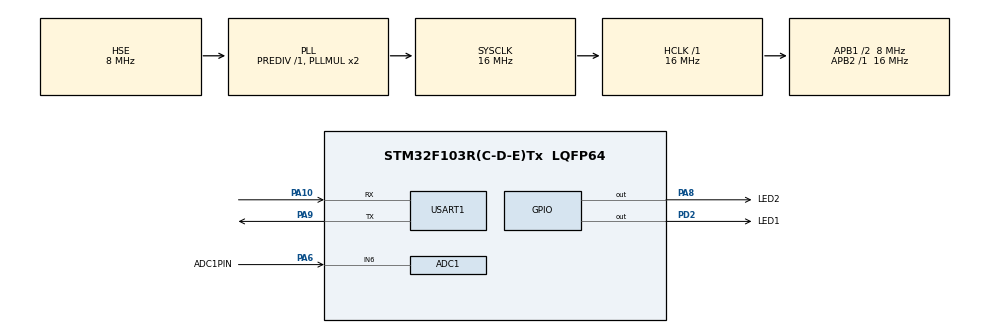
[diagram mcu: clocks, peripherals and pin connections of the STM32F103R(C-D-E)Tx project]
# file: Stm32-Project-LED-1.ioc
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ADC1.Channel-0\#ChannelRegularConversion=ADC_CHANNEL_6
ADC1.NbrOfConversionFlag=1
ADC1.Rank-0\#ChannelRegularConversion=1
ADC1.SamplingTime-0\#ChannelRegularConversion=ADC_SAMPLETIME_1CYCLE_5
ADC1.master=1
Mcu.Family=STM32F1
Mcu.Name=STM32F103R(C-D-E)Tx
Mcu.Package=LQFP64
NVIC.PriorityGroup=NVIC_PRIORITYGROUP_4
PA10.Mode=Asynchronous
PA10.Signal=USART1_RX
PA13.Mode=Serial_Wire
PA13.Signal=SYS_JTMS-SWDIO
PA14.Mode=Serial_Wire
PA14.Signal=SYS_JTCK-SWCLK
PA6.GPIO_Label=ADC1PIN
PA6.Signal=ADCx_IN6
PA8.GPIO_Label=LED2
PA8.GPIO_PuPd=GPIO_PULLUP
PA8.GPIO_Speed=GPIO_SPEED_FREQ_HIGH
PA8.PinState=GPIO_PIN_SET
PA8.Signal=GPIO_Output
PA9.Mode=Asynchronous
PA9.Signal=USART1_TX
PD0-OSC_IN.Mode=HSE-External-Oscillator
PD0-OSC_IN.Signal=RCC_OSC_IN
PD1-OSC_OUT.Mode=HSE-External-Oscillator
PD1-OSC_OUT.Signal=RCC_OSC_OUT
PD2.GPIO_Label=LED1
PD2.GPIO_PuPd=GPIO_PULLUP
PD2.GPIO_Speed=GPIO_SPEED_FREQ_HIGH
PD2.PinState=GPIO_PIN_SET
PD2.Signal=GPIO_Output
ProjectManager.HeapSize=0x200
ProjectManager.StackSize=0x400
ProjectManager.TargetToolchain=MDK-ARM V5.32
RCC.ADCPresc=RCC_ADCPCLK2_DIV8
RCC.AHBFreq_Value=16000000
RCC.APB1CLKDivider=RCC_HCLK_DIV2
RCC.APB1Freq_Value=8000000
RCC.APB1TimFreq_Value=16000000
RCC.APB2Freq_Value=16000000
RCC.APB2TimFreq_Value=16000000
RCC.HCLKFreq_Value=16000000
RCC.PLLSourceVirtual=RCC_PLLSOURCE_HSE
RCC.SYSCLKFreq_VALUE=16000000
RCC.SYSCLKSource=RCC_SYSCLKSOURCE_PLLCLK
RCC.USBFreq_Value=16000000
SH.ADCx_IN6.0=ADC1_IN6,IN6
USART1.VirtualMode=VM_ASYNC
board=custom

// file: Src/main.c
/* USER CODE BEGIN Header */
/**
  ******************************************************************************
  * @file           : main.c
  * @brief          : Main program body
  ******************************************************************************
  * @attention
  *
  * Copyright (c) 2023 STMicroelectronics.
  * All rights reserved.
  *
  * This software is licensed under terms that can be found in the LICENSE file
  * in the root directory of this software component.
  * If no LICENSE file comes with this software, it is provided AS-IS.
  *
  ******************************************************************************
  */
/* USER CODE END Header */
#include "main.h"
#include "adc.h"
#include "usart.h"
#include "gpio.h"

/* USER CODE BEGIN Includes */
#include "stdio.h"
/* USER CODE END Includes */

/* USER CODE BEGIN PV */
uint16_t ADC1Val=0;
//char ss[]="";
/* USER CODE END PV */

void SystemClock_Config(void);

/* USER CODE BEGIN 0 */
int fputc(int ch,FILE *f)
{
	HAL_UART_Transmit(&huart1,(uint8_t *) &ch,1,0xfff);
	return ch;
}
/* USER CODE END 0 */

int main(void)
{

  /* MCU Configuration--------------------------------------------------------*/

  /* Reset of all peripherals, Initializes the Flash interface and the Systick. */
  HAL_Init();

  /* Configure the system clock */
  SystemClock_Config();

  /* Initialize all configured peripherals */
  MX_GPIO_Init();
  MX_USART1_UART_Init();
  MX_ADC1_Init();
  /* USER CODE BEGIN 2 */
	HAL_ADCEx_Calibration_Start(&hadc1);//初始化校准
  /* USER CODE END 2 */

  /* Infinite loop */
  /* USER CODE BEGIN WHILE */
  while (1)
  {
		HAL_ADC_Start(&hadc1);	//Start ADC
		HAL_ADC_PollForConversion(&hadc1,50);//轮询方式，超时50ms等待转化完成
		if(HAL_IS_BIT_SET(HAL_ADC_GetState(&hadc1),HAL_ADC_STATE_REG_EOC))//判断是否转化成功
		{
			ADC1Val = HAL_ADC_GetValue(&hadc1);
			printf("ADC1 Reading ：%d \r\n",ADC1Val);
			printf("PA6 True Voltage value ：%.4f \r\n",ADC1Val*3.3f/4096);
//			sprintf(ss,"ADC1 Reading ：%d \r\n",ADC1Val);
//			HAL_UART_Transmit(&huart1,(uint8_t *)ss,strlen(ss),0xffff);
//			sprintf(ss,"PA6 True Voltage value ：%.4f \r\n",ADC1Val*3.3f/4096);
//			HAL_UART_Transmit(&huart1,(uint8_t *)ss,strlen(ss),0xffff);
		}
		HAL_Delay(1000);
    /* USER CODE END WHILE */

  }
}

void SystemClock_Config(void)
{
  RCC_OscInitTypeDef RCC_OscInitStruct = {0};
  RCC_ClkInitTypeDef RCC_ClkInitStruct = {0};
  RCC_PeriphCLKInitTypeDef PeriphClkInit = {0};

  /** Initializes the RCC Oscillators according to the specified parameters
  * in the RCC_OscInitTypeDef structure.
  */
  RCC_OscInitStruct.OscillatorType = RCC_OSCILLATORTYPE_HSE;
  RCC_OscInitStruct.HSEState = RCC_HSE_ON;
  RCC_OscInitStruct.HSEPredivValue = RCC_HSE_PREDIV_DIV1;
  RCC_OscInitStruct.HSIState = RCC_HSI_ON;
  RCC_OscInitStruct.PLL.PLLState = RCC_PLL_ON;
  RCC_OscInitStruct.PLL.PLLSource = RCC_PLLSOURCE_HSE;
  RCC_OscInitStruct.PLL.PLLMUL = RCC_PLL_MUL2;
  if (HAL_RCC_OscConfig(&RCC_OscInitStruct) != HAL_OK)
  {
    Error_Handler();
  }

  /** Initializes the CPU, AHB and APB buses clocks
  */
  RCC_ClkInitStruct.ClockType = RCC_CLOCKTYPE_HCLK|RCC_CLOCKTYPE_SYSCLK
                              |RCC_CLOCKTYPE_PCLK1|RCC_CLOCKTYPE_PCLK2;
  RCC_ClkInitStruct.SYSCLKSource = RCC_SYSCLKSOURCE_PLLCLK;
  RCC_ClkInitStruct.AHBCLKDivider = RCC_SYSCLK_DIV1;
  RCC_ClkInitStruct.APB1CLKDivider = RCC_HCLK_DIV2;
  RCC_ClkInitStruct.APB2CLKDivider = RCC_HCLK_DIV1;

  if (HAL_RCC_ClockConfig(&RCC_ClkInitStruct, FLASH_LATENCY_0) != HAL_OK)
  {
    Error_Handler();
  }
  PeriphClkInit.PeriphClockSelection = RCC_PERIPHCLK_ADC;
  PeriphClkInit.AdcClockSelection = RCC_ADCPCLK2_DIV8;
  if (HAL_RCCEx_PeriphCLKConfig(&PeriphClkInit) != HAL_OK)
  {
    Error_Handler();
  }
}

void Error_Handler(void)
{
  __disable_irq();
  while (1)
  {
  }
}
